# MIK32 register map
Vendor: Mikron; Series: MIK32; File version: 1.0
Registers are 32-bit, read-write, reset 0x0 unless marked. A register's access mark holds for its fields unless they carry their own. Offsets are from the block's base; [hi:lo] are bit positions.

## EEPROM_REGS — Контроллер EEPROM (8Кб)
Base 0x00070400
0x00 EEDAT — Регистр чтения/записи данных
  [31:0] DATA — В процессе чтения/записи данного регистра производится автоматическое инкрементирование адреса (EEA).
0x04 EEA — Регистр адреса страницы
  [12:2] ADDR wo — Адрес слова для выполнения стирания/програмирования /чтения. Если необходимо выполнить стирание или программирование, данный адрес должен использоваться в процедуре заполнения буфера записи
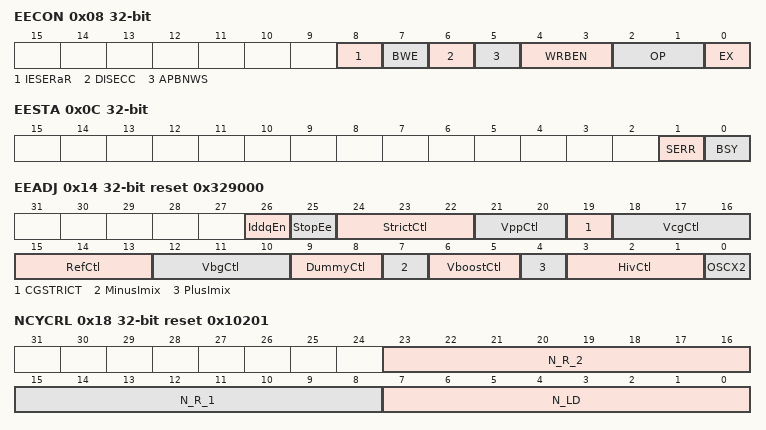
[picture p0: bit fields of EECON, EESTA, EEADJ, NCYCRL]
0x08 EECON — Регистр управления
  [8] IESERaR wo — Разрешение запроса прерывания при поднятии флага SERR
    0=Disable (Запрос не поступает); 1=Enable (Запрос поступает)
  [7] BWE wo — Разрешение записи в буфер. Данный бит следует устанавливать в «1» перед операцией заполнения буфера записи перед операциями стирания и программирования. После операций стирания и программирования данный бит автоматически очищается (то есть для последующей записи в буфер следует повторно выполнить запись «1» в этот бит)
  [6] DISECC wo — Отключение схемы коррекции ошибок во время выполнения запрошенной процедуры. Отлючение производится записью «1» в этот бит. Если схема коррекции отключена, то при записи значение бит коррекции определяется шестью младшими битами слова. Если схема коррекции включена, то при записи значение бит коррекции вычисляется схемой SEC32 - ENC. Если схема коррекции отключена, то при чтении не производится коррекция возможных ошибок в слове. Если схема коррекции включена, то при чтении данные корректируются схемой DEC32_ENC
    0=Disable (Включение схемы коррекции ошибок во время выполнения запрошенной процедуры); 1=Enable (Отключение схемы коррекции ошибок во время выполнения запрошенной процедуры)
  [5] APBNWS wo — Отключение вставки тактов ожидания в процессе обмена по APB при заполнении буфера записи (во время записи в EEDAT) и при записи адреса для процедуры чтения данных (EEA). Если такты ожидания отключены (APBNWS=1), то требуется производить опрос флага EESTA.BSY после этих операций до тех пор, пока EESTA.BSY не станет равным 0
    0=Disable (Такты ожидания включены); 1=Enable (Такты ожидания отключены)
  [4:3] WRBEN wo — Поведение операции стирания/програмирования. Данные биты должны быть установлены перед операцией заполнения буфера записи перед операциями стирания и программирования
    0=One_page (обычное стирание/програмирование одной страницы;); 1=Even_pages (стирание/програмирование всех четных страниц;); 2=Odd_pages (стирание/програмирование всех нечетных страниц;); 3=All_pages (стирание/програмирование всех страниц.)
  [2:1] OP wo — Выбор процедуры
    0=Read_page (Чтение страницы); 1=Erase (Стирание); 2=Programming (Программирование)
  [0] EX wo — Запуск процедуры. Запись 1 в данный бит инициирует выпол-нение процедуры, процедура определяется битами OP
0x0C EESTA — Регистр статуса
  [1] SERR wo write-0-clears — Индикатор одиночной (исправимой) ошибки. Аппаратно может быть только поднят, т.е. если после слова с ошибкой считано слово без ошибки, флаг не очистится. Может быть очищен программно путем записи 0
  [0] BSY ro — Блок занят (выполняется запрошенная операция)
    0=Ready (Блок готов); 1=Busy (Блок занят (выполняется запрошенная операция))
0x10 EERB ro — Регистр бит коррекции прочитанного слова
  [5:0] CORRECT — Содержит 6 бит коррекции последнего считанного слова
0x14 EEADJ reset 0x329000 — Регистр настроек
  [26] IddqEn — Перевод Hard IP в состояние бездействия (quiescent) для Iddq тестирования. Поле предназначено для тонкой настройки блока и выполнения процедуры тестирование. Не гарантируется работа блока при использовании не рекомендованных производителем значений.
  [25] StopEe — Перевод Hard IP в режим пониженного энергопотребления
  [24:22] StrictCtl — Точная подстройка тока, используемого при чтении. Поле предназначено для тонкой настройки блока и выполнения процедуры тестирование. Не гарантируется работа блока при использовании не рекомендованных производителем значений.
  [21:20] VppCtl — Подстройка времени нарастания высокого напряжения. Поле предназначено для тонкой настройки блока и выполнения процедуры тестирование. Не гарантируется работа блока при использовании не рекомендованных производителем значений.
  [19] CGSTRICT — Включение режима точной подстройки напряжения, используемого при чтении. Поле предназначено для тонкой настройки блока и выполнения процедуры тестирование. Не гарантируется работа блока при использовании не рекомендованных производителем значений.
  [18:16] VcgCtl — Подстройка напряжения, подаваемого на управляющие затворы при чтении. Поле предназначено для тонкой настройки блока и выполнения процедуры тестирование. Не гарантируется работа блока при использовании не рекомендованных производителем значений.
  [15:13] RefCtl — Подстройка тока, используемого при чтении. Поле предназначено для тонкой настройки блока и выполнения процедуры тестирование. Не гарантируется работа блока при использовании не рекомендованных производителем значений.
  [12:10] VbgCtl — Подстройка опорного напряжения bandgap. Поле предназначено для тонкой настройки блока и выполнения процедуры тестирование. Не гарантируется работа блока при использовании не рекомендованных производителем значений.
  [9:8] DummyCtl — Подстройка момента захвата выдаваемых данных. Поле предназначено для тонкой настройки блока и выполнения процедуры тестирование. Не гарантируется работа блока при использовании не рекомендованных производителем значений.
  [7] MinusImix — Сигнал управления блоком мониторинга аналоговых сигналов. Поле предназначено для тонкой настройки блока и выполнения процедуры тестирование. Не гарантируется работа блока при использовании не рекомендованных производителем значений.
  [6:5] VboostCtl — Старший разряд - подстройка внутреннего сигнала Vboost, младший разряд - сигнал управления блоком мониторинга аналоговых сигналов. Поле предназначено для тонкой настройки блока и выполнения процедуры тестирование. Не гарантируется работа блока при использовании не рекомендованных производителем значений.
  [4] PlusImix — Сигнал управления блоком мониторинга аналоговых сигналов. Поле предназначено для тонкой настройки блока и выполнения процедуры тестирование. Не гарантируется работа блока при использовании не рекомендованных производителем значений.
  [3:1] HivCtl — Подстройка уровня внутреннего сигнала HIV. Поле предназначено для тонкой настройки блока и выполнения процедуры тестирование. Не гарантируется работа блока при использовании не рекомендованных производителем значений.
  [0] OSCX2 — Увеличение частоты тактового сигнала, поступающего на устройство с зарядовой накачкой, в два раза. Поле предназначено для тонкой настройки блока и выполнения процедуры тестирование. Не гарантируется работа блока при использовании не рекомендованных производителем значений.
0x18 NCYCRL reset 0x10201 — Регистр подстройки длительности процедур чтения и заполнения буфера записи
  [23:16] N_R_2 — Количество тактов, требуемое для завершения процедуры чтения (перевода OkSelEe на высокий уровень после процедуры чтения). Рекомендуемое значение при любых частотах clk 1 такт. Запрещено устанавливать равным 0
  [15:8] N_R_1 — Количество тактов, в течение которого Phi1ShiftEe имеет высокий уровень в процедуре чтения. Рекомендуемое значение N RA = ceil(51/Pclk), где Pclk – период тактового сигнала в нс, ceil – функция округления до ближайшего большего целого числа. Запрещено устанавливать равным 0
  [7:0] N_LD — Количество тактов между передними и задними фронтами сигналов Hard IP Phi1Ee и Phi1ShiftEe и задержка от начала обращения по шине до первого фронта Phi1Ee. Рекомендуемое значение при любых частотах clk 1 такт. Запрещено устанавливать равным 0
0x1C NCYCEP1 reset 0x1046B — Регистр 1 подстройки длительности процедур стирания и программирования
  [17:0] N_EP_1 — Длительность высокого уровня сигнала BUSY (вход Hard IP) в тактах. Рекомендуемое значение N RA = 2000000 нс / Pclk, где Pclk – период тактового сигнала в нс. Пример – 66667 тактов для частоты Fclk = 33,3 МГц. Запрещено устанавливать равным 0
0x20 NCYCEP2 reset 0x32 — Регистр 2 подстройки длительности процедур стирания и программирования
  [10:0] N_EP_2 — Задержка между задними фронтами BUSY и HvonValid (входы Hard IP) в тактах. Рекомендуемое значение N RA = 15000 нс / Pclk, где Pclk – период тактового сигнала в нс. Пример – 500 тактов для частоты Fclk = 33,3 МГц. Запрещено устанавливать равным 0
